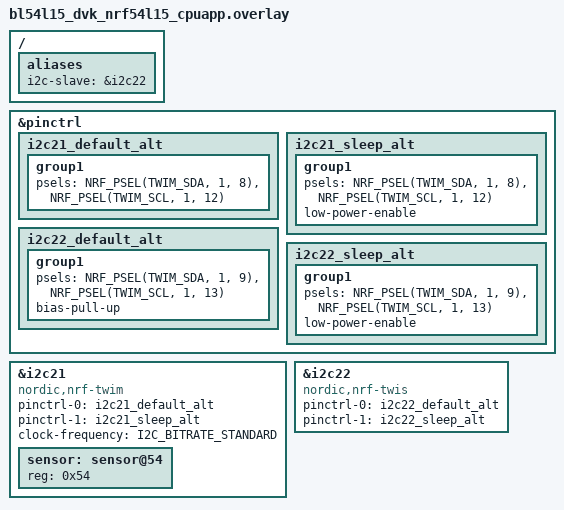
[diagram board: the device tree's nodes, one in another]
/*
 * Copyright 2024 Nordic Semiconductor ASA
 * Copyright 2025 Ezurio LLC
 * SPDX-License-Identifier: Apache-2.0
 */

/ {
	aliases {
		i2c-slave = &i2c22;
	};
};

&pinctrl {
	i2c21_default_alt: i2c21_default_alt {
		group1 {
			psels = <NRF_PSEL(TWIM_SDA, 1, 8)>,
				<NRF_PSEL(TWIM_SCL, 1, 12)>;
		};
	};

	i2c21_sleep_alt: i2c21_sleep_alt {
		group1 {
			psels = <NRF_PSEL(TWIM_SDA, 1, 8)>,
				<NRF_PSEL(TWIM_SCL, 1, 12)>;
			low-power-enable;
		};
	};

	i2c22_default_alt: i2c22_default_alt {
		group1 {
			/* Temporary workaround as it is currently not possible
			 * to configure pins for TWIS with pinctrl.
			 */
			psels = <NRF_PSEL(TWIM_SDA, 1, 9)>,
				<NRF_PSEL(TWIM_SCL, 1, 13)>;
			bias-pull-up;
		};
	};

	i2c22_sleep_alt: i2c22_sleep_alt {
		group1 {
			psels = <NRF_PSEL(TWIM_SDA, 1, 9)>,
				<NRF_PSEL(TWIM_SCL, 1, 13)>;
			low-power-enable;
		};
	};
};

dut_twim: &i2c21 {
	compatible = "nordic,nrf-twim";
	status = "okay";
	pinctrl-0 = <&i2c21_default_alt>;
	pinctrl-1 = <&i2c21_sleep_alt>;
	pinctrl-names = "default", "sleep";
	clock-frequency = <I2C_BITRATE_STANDARD>;
	sensor: sensor@54 {
		reg = <0x54>;
	};
};

&i2c22 {
	compatible = "nordic,nrf-twis";
	status = "okay";
	pinctrl-0 = <&i2c22_default_alt>;
	pinctrl-1 = <&i2c22_sleep_alt>;
	pinctrl-names = "default", "sleep";
};
